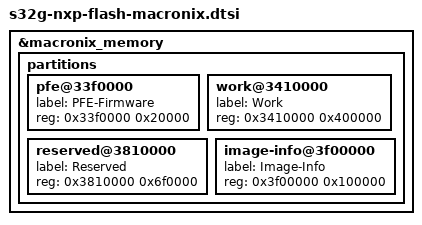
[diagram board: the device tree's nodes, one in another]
// SPDX-License-Identifier: (GPL-2.0+ OR BSD-3-Clause)
/*
 * Copyright 2022-2024 NXP
 */

#include "s32cc-nxp-flash-macronix.dtsi"

&macronix_memory {
	partitions {
		pfe@33f0000 {
			label = "PFE-Firmware";
			reg = <0x33f0000 0x20000>;
		};
		work@3410000 {
			label = "Work";
			reg = <0x3410000 0x400000>;
		};
		reserved@3810000 {
			label = "Reserved";
			reg = <0x3810000 0x6f0000>;
		};
		image-info@3f00000 {
			label = "Image-Info";
			reg = <0x3f00000 0x100000>;
		};
	};
};
